AUTOSAR XML (schema 4-0-3)
package /ComponentTypes
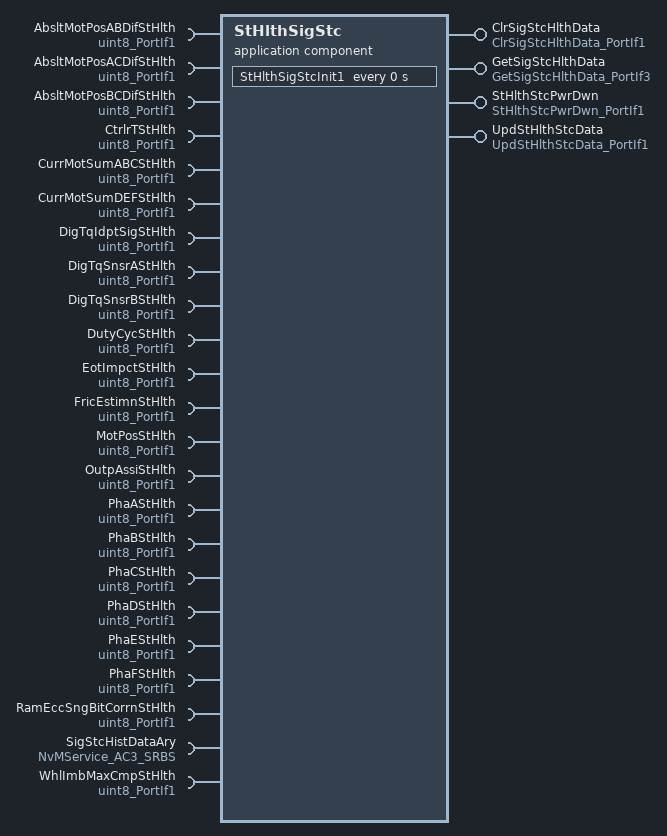
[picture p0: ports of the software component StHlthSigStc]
  application sw component type StHlthSigStc
    4 x provide port, all with server-com-spec{operation=Oper, queue-length=1}:
      ClrSigStcHlthData: provided-interface=ClrSigStcHlthData_PortIf1
      GetSigStcHlthData: provided-interface=GetSigStcHlthData_PortIf3
      StHlthStcPwrDwn: provided-interface=StHlthStcPwrDwn_PortIf1
      UpdStHlthStcData: provided-interface=UpdStHlthStcData_PortIf1
    23 x require port:
      AbsltMotPosABDifStHlth: nonqueued-receiver-com-spec{data-element=Val, filter=data-filter-type=ALWAYS, init-value=100}, required-interface=uint8_PortIf1
      AbsltMotPosACDifStHlth: nonqueued-receiver-com-spec{data-element=Val, filter=data-filter-type=ALWAYS, init-value=100}, required-interface=uint8_PortIf1
      AbsltMotPosBCDifStHlth: nonqueued-receiver-com-spec{data-element=Val, filter=data-filter-type=ALWAYS, init-value=100}, required-interface=uint8_PortIf1
      CtrlrTStHlth: nonqueued-receiver-com-spec{data-element=Val, filter=data-filter-type=ALWAYS, init-value=100}, required-interface=uint8_PortIf1
      CurrMotSumABCStHlth: nonqueued-receiver-com-spec{data-element=Val, filter=data-filter-type=ALWAYS, init-value=100}, required-interface=uint8_PortIf1
      CurrMotSumDEFStHlth: nonqueued-receiver-com-spec{data-element=Val, filter=data-filter-type=ALWAYS, init-value=100}, required-interface=uint8_PortIf1
      DigTqIdptSigStHlth: nonqueued-receiver-com-spec{data-element=Val, filter=data-filter-type=ALWAYS, init-value=100}, required-interface=uint8_PortIf1
      DigTqSnsrAStHlth: nonqueued-receiver-com-spec{data-element=Val, filter=data-filter-type=ALWAYS, init-value=100}, required-interface=uint8_PortIf1
      DigTqSnsrBStHlth: nonqueued-receiver-com-spec{data-element=Val, filter=data-filter-type=ALWAYS, init-value=100}, required-interface=uint8_PortIf1
      DutyCycStHlth: nonqueued-receiver-com-spec{data-element=Val, filter=data-filter-type=ALWAYS, init-value=100}, required-interface=uint8_PortIf1
      EotImpctStHlth: nonqueued-receiver-com-spec{data-element=Val, filter=data-filter-type=ALWAYS, init-value=100}, required-interface=uint8_PortIf1
      FricEstimnStHlth: nonqueued-receiver-com-spec{data-element=Val, filter=data-filter-type=ALWAYS, init-value=100}, required-interface=uint8_PortIf1
      MotPosStHlth: nonqueued-receiver-com-spec{data-element=Val, filter=data-filter-type=ALWAYS, init-value=100}, required-interface=uint8_PortIf1
      OutpAssiStHlth: nonqueued-receiver-com-spec{data-element=Val, filter=data-filter-type=ALWAYS, init-value=100}, required-interface=uint8_PortIf1
      PhaAStHlth: nonqueued-receiver-com-spec{data-element=Val, filter=data-filter-type=ALWAYS, init-value=100}, required-interface=uint8_PortIf1
      PhaBStHlth: nonqueued-receiver-com-spec{data-element=Val, filter=data-filter-type=ALWAYS, init-value=100}, required-interface=uint8_PortIf1
      PhaCStHlth: nonqueued-receiver-com-spec{data-element=Val, filter=data-filter-type=ALWAYS, init-value=100}, required-interface=uint8_PortIf1
      PhaDStHlth: nonqueued-receiver-com-spec{data-element=Val, filter=data-filter-type=ALWAYS, init-value=100}, required-interface=uint8_PortIf1
      PhaEStHlth: nonqueued-receiver-com-spec{data-element=Val, filter=data-filter-type=ALWAYS, init-value=100}, required-interface=uint8_PortIf1
      PhaFStHlth: nonqueued-receiver-com-spec{data-element=Val, filter=data-filter-type=ALWAYS, init-value=100}, required-interface=uint8_PortIf1
      RamEccSngBitCorrnStHlth: nonqueued-receiver-com-spec{data-element=Val, filter=data-filter-type=ALWAYS, init-value=100}, required-interface=uint8_PortIf1
      SigStcHistDataAry: required-interface=NvMService_AC3_SRBS
      WhlImbMaxCmpStHlth: nonqueued-receiver-com-spec{data-element=Val, filter=data-filter-type=ALWAYS, init-value=100}, required-interface=uint8_PortIf1
    behavior StHlthSigStc_InternalBehavior: port-api-option{enable-take-address=false, indirect-api=false, port=SigStcHistDataAry}
      exclusive area StHlthSigStc_ExclusiveArea
      ar-typed-per-instance-memorys:
        5 x data, all with sw-calibration-access=READ-ONLY:
          IgnCycSampleCntrAry: type=Ary1D_u32_StHlthSigStc1
          RamBuf: type=Ary1D_u8_StHlthSigStc1
          SigAvrgBuf: type=Ary1D_f32_StHlthSigStc1
          SigStcHistDataAry: type=Ary1D_u8_225
          VldNvm: type=boolean
      operation invoked event OIT_StHlthSigStcClrStcData_Oper_ClrSigStcHlthData_Oper: start-on-event=ClrSigStcHlthData_Oper, operation=ClrSigStcHlthData.Oper
      operation invoked event OIT_GetSigStcHlthData_Oper_GetSigStcHlthData_Oper: start-on-event=GetSigStcHlthData_Oper, operation=GetSigStcHlthData.Oper
      timing event StHlthSigStc_InitEvent: start-on-event=StHlthSigStcInit1, period=0
      operation invoked event OIT_StHlthStcPwrDwn_Oper_StHlthStcPwrDwn_Oper: start-on-event=StHlthStcPwrDwn_Oper, operation=StHlthStcPwrDwn.Oper
      operation invoked event OIT_UpdStHlthStcData_Oper_UpdStHlthStcData_Oper: start-on-event=UpdStHlthStcData_Oper, operation=UpdStHlthStcData.Oper
      5 x runnable:
        ClrSigStcHlthData_Oper: can-be-invoked-concurrently=true
          sync call SC_StHlthSigStcHistDataAry_SetRamBlockStatus: operation=SigStcHistDataAry.SetRamBlockStatus, timeout=0
        GetSigStcHlthData_Oper: can-enter-exclusive-area=StHlthSigStc_ExclusiveArea, can-be-invoked-concurrently=true
        StHlthSigStcInit1
          sync call SC_StHlthSigStcHistDataAry_GetErrorStatus: operation=SigStcHistDataAry.GetErrorStatus, timeout=0
        StHlthStcPwrDwn_Oper: can-be-invoked-concurrently=true
          sync call SC_StHlthSigStcHistDataAry_SetRamBlockStatus: operation=SigStcHistDataAry.SetRamBlockStatus, timeout=0
        UpdStHlthStcData_Oper: can-enter-exclusive-area=StHlthSigStc_ExclusiveArea, can-be-invoked-concurrently=true
          data-receive-point-by-arguments:
            22 x access:
              REC_AbsltMotPosABDifStHlth_Val: accessed-variable=AbsltMotPosABDifStHlth.Val
              REC_AbsltMotPosACDifStHlth_Val: accessed-variable=AbsltMotPosACDifStHlth.Val
              REC_AbsltMotPosBCDifStHlth_Val: accessed-variable=AbsltMotPosBCDifStHlth.Val
              REC_CtrlrTStHlth_Val: accessed-variable=CtrlrTStHlth.Val
              REC_CurrMotSumABCStHlth_Val: accessed-variable=CurrMotSumABCStHlth.Val
              REC_CurrMotSumDEFStHlth_Val: accessed-variable=CurrMotSumDEFStHlth.Val
              REC_DigTqIdptSigStHlth_Val: accessed-variable=DigTqIdptSigStHlth.Val
              REC_DigTqSnsrAStHlth_Val: accessed-variable=DigTqSnsrAStHlth.Val
              REC_DigTqSnsrBStHlth_Val: accessed-variable=DigTqSnsrBStHlth.Val
              REC_DutyCycStHlth_Val: accessed-variable=DutyCycStHlth.Val
              REC_EotImpctStHlth_Val: accessed-variable=EotImpctStHlth.Val
              REC_FricEstimnStHlth_Val: accessed-variable=FricEstimnStHlth.Val
              REC_MotPosStHlth_Val: accessed-variable=MotPosStHlth.Val
              REC_OutpAssiStHlth_Val: accessed-variable=OutpAssiStHlth.Val
              REC_PhaAStHlth_Val: accessed-variable=PhaAStHlth.Val
              REC_PhaBStHlth_Val: accessed-variable=PhaBStHlth.Val
              REC_PhaCStHlth_Val: accessed-variable=PhaCStHlth.Val
              REC_PhaDStHlth_Val: accessed-variable=PhaDStHlth.Val
              REC_PhaEStHlth_Val: accessed-variable=PhaEStHlth.Val
              REC_PhaFStHlth_Val: accessed-variable=PhaFStHlth.Val
              REC_RamEccSngBitCorrnStHlth_Val: accessed-variable=RamEccSngBitCorrnStHlth.Val
              REC_WhlImbMaxCmpStHlth_Val: accessed-variable=WhlImbMaxCmpStHlth.Val
      swc service dependency NvmSigStcHistDataAry: assigned-datas=role-based-data-assignment={role=ramBlock, used-data-element=SigStcHistDataAry}
        assigned-ports:
          port-prototype=SigStcHistDataAry, role=NvMService_AC3_SRBS
          port-prototype=SigStcHistDataAry, role=NvMService_AC3_SRBS
        service-needs:
          nv block needs NvmSigStcHistDataAry: n-data-sets=0, readonly=false, reliability=ERROR-DETECTION, resistant-to-changed-sw=true, restore-at-start=true, store-at-shutdown=true, write-only-once=false, writing-frequency=0, writing-priority=LOW
  swc implementation StHlthSigStc_Implementation: behavior=StHlthSigStc_InternalBehavior
    code-descriptors:
      code Default: artifact-descriptors=autosar-engineering-object={short-label=Default, category=SWSRC}
